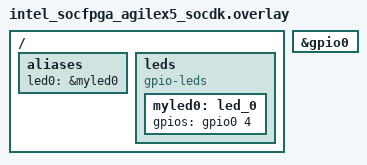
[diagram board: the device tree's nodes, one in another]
/*
 * Copyright (C) 2023 Intel Corporation
 *
 * SPDX-License-Identifier: Apache-2.0
 */

#include <dt-bindings/gpio/gpio.h>

/ {
	aliases {
		led0 = &myled0;
	};

	leds {
		compatible = "gpio-leds";
		myled0: led_0 {
			gpios = <&gpio0 4 GPIO_ACTIVE_HIGH>;
		};
	};
};

&gpio0 {
	status = "okay";
};
